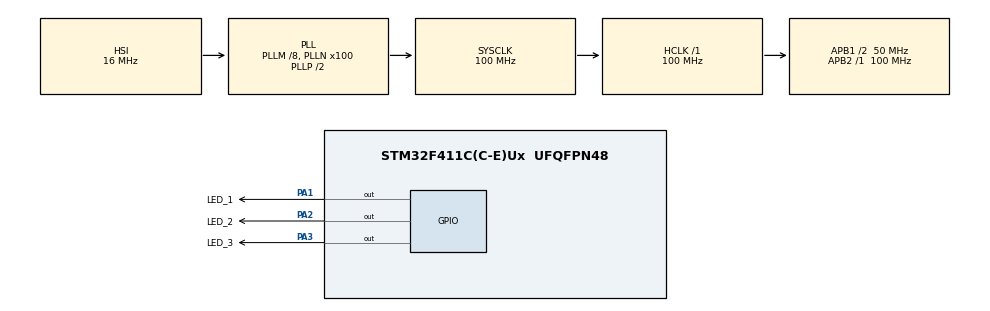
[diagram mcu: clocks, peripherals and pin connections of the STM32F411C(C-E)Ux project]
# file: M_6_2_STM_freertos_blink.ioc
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FREERTOS.Tasks01=defaultTask,24,128,StartDefaultTask,Default,NULL,Dynamic,NULL,NULL;myLedTask01,24,128,StartLedTask01,Default,NULL,Dynamic,NULL,NULL;myLedTask02,24,128,StartLedTask02,Default,NULL,Dynamic,NULL,NULL;myLedTask03,24,128,StartLedTask03,Default,NULL,Dynamic,NULL,NULL
FREERTOS.configUSE_NEWLIB_REENTRANT=1
Mcu.Family=STM32F4
Mcu.Name=STM32F411C(C-E)Ux
Mcu.Package=UFQFPN48
NVIC.PriorityGroup=NVIC_PRIORITYGROUP_4
NVIC.TIM2_IRQn=true\:15\:0\:false\:false\:true\:false\:false\:true\:true
NVIC.TimeBase=TIM2_IRQn
NVIC.TimeBaseIP=TIM2
PA1.GPIO_Label=LED_1
PA1.Signal=GPIO_Output
PA13.Mode=Serial_Wire
PA13.Signal=SYS_JTMS-SWDIO
PA14.Mode=Serial_Wire
PA14.Signal=SYS_JTCK-SWCLK
PA2.GPIO_Label=LED_2
PA2.Signal=GPIO_Output
PA3.GPIO_Label=LED_3
PA3.Signal=GPIO_Output
PC14-OSC32_IN.Mode=LSE-External-Oscillator
PC14-OSC32_IN.Signal=RCC_OSC32_IN
PC15-OSC32_OUT.Mode=LSE-External-Oscillator
PC15-OSC32_OUT.Signal=RCC_OSC32_OUT
PH0\ -\ OSC_IN.Mode=HSE-External-Oscillator
PH0\ -\ OSC_IN.Signal=RCC_OSC_IN
PH1\ -\ OSC_OUT.Mode=HSE-External-Oscillator
PH1\ -\ OSC_OUT.Signal=RCC_OSC_OUT
ProjectManager.HeapSize=0x200
ProjectManager.StackSize=0x400
ProjectManager.TargetToolchain=STM32CubeIDE
RCC.48MHZClocksFreq_Value=50000000
RCC.AHBFreq_Value=100000000
RCC.APB1CLKDivider=RCC_HCLK_DIV2
RCC.APB1Freq_Value=50000000
RCC.APB1TimFreq_Value=100000000
RCC.APB2Freq_Value=100000000
RCC.APB2TimFreq_Value=100000000
RCC.CortexFreq_Value=100000000
RCC.HCLKFreq_Value=100000000
RCC.HSE_VALUE=25000000
RCC.HSI_VALUE=16000000
RCC.PLLM=8
RCC.PLLN=100
RCC.SYSCLKFreq_VALUE=100000000
RCC.SYSCLKSource=RCC_SYSCLKSOURCE_PLLCLK
RCC.VCOOutputFreq_Value=200000000
VP_FREERTOS_VS_CMSIS_V2.Mode=CMSIS_V2
VP_SYS_VS_tim2.Mode=TIM2
board=custom

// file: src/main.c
/* USER CODE BEGIN Header */
/**
 ******************************************************************************
 * @file           : main.c
 * @brief          : Main program body
 ******************************************************************************
 * @attention
 *
 * Copyright (c) 2026 STMicroelectronics.
 * All rights reserved.
 *
 * This software is licensed under terms that can be found in the LICENSE file
 * in the root directory of this software component.
 * If no LICENSE file comes with this software, it is provided AS-IS.
 *
 ******************************************************************************
 */
/* USER CODE END Header */
#include "main.h"
#include "cmsis_os.h"

/* Definitions for defaultTask */
osThreadId_t defaultTaskHandle;
const osThreadAttr_t defaultTask_attributes = {
    .name = "defaultTask",
    .stack_size = 128 * 4,
    .priority = (osPriority_t)osPriorityNormal,
};
/* Definitions for myLedTask01 */
osThreadId_t myLedTask01Handle;
const osThreadAttr_t myLedTask01_attributes = {
    .name = "myLedTask01",
    .stack_size = 128 * 4,
    .priority = (osPriority_t)osPriorityNormal,
};
/* Definitions for myLedTask02 */
osThreadId_t myLedTask02Handle;
const osThreadAttr_t myLedTask02_attributes = {
    .name = "myLedTask02",
    .stack_size = 128 * 4,
    .priority = (osPriority_t)osPriorityNormal,
};
/* Definitions for myLedTask03 */
osThreadId_t myLedTask03Handle;
const osThreadAttr_t myLedTask03_attributes = {
    .name = "myLedTask03",
    .stack_size = 128 * 4,
    .priority = (osPriority_t)osPriorityNormal,
};

void SystemClock_Config(void);
static void MX_GPIO_Init(void);
void StartDefaultTask(void *argument);
void StartLedTask01(void *argument);
void StartLedTask02(void *argument);
void StartLedTask03(void *argument);

int main(void)
{

  /* MCU Configuration--------------------------------------------------------*/

  /* Reset of all peripherals, Initializes the Flash interface and the Systick. */
  HAL_Init();

  /* Configure the system clock */
  SystemClock_Config();

  /* Initialize all configured peripherals */
  MX_GPIO_Init();

  /* Init scheduler */
  osKernelInitialize();

  /* Create the thread(s) */
  /* creation of defaultTask */
  defaultTaskHandle = osThreadNew(StartDefaultTask, NULL, &defaultTask_attributes);

  /* creation of myLedTask01 */
  myLedTask01Handle = osThreadNew(StartLedTask01, NULL, &myLedTask01_attributes);

  /* creation of myLedTask02 */
  myLedTask02Handle = osThreadNew(StartLedTask02, NULL, &myLedTask02_attributes);

  /* creation of myLedTask03 */
  myLedTask03Handle = osThreadNew(StartLedTask03, NULL, &myLedTask03_attributes);

  /* Start scheduler */
  osKernelStart();

  /* We should never get here as control is now taken by the scheduler */

  /* Infinite loop */
  while (1)
  {

  }
}

void SystemClock_Config(void)
{
  RCC_OscInitTypeDef RCC_OscInitStruct = {0};
  RCC_ClkInitTypeDef RCC_ClkInitStruct = {0};

  /** Configure the main internal regulator output voltage
   */
  __HAL_RCC_PWR_CLK_ENABLE();
  __HAL_PWR_VOLTAGESCALING_CONFIG(PWR_REGULATOR_VOLTAGE_SCALE1);

  /** Initializes the RCC Oscillators according to the specified parameters
   * in the RCC_OscInitTypeDef structure.
   */
  RCC_OscInitStruct.OscillatorType = RCC_OSCILLATORTYPE_HSI;
  RCC_OscInitStruct.HSIState = RCC_HSI_ON;
  RCC_OscInitStruct.HSICalibrationValue = RCC_HSICALIBRATION_DEFAULT;
  RCC_OscInitStruct.PLL.PLLState = RCC_PLL_ON;
  RCC_OscInitStruct.PLL.PLLSource = RCC_PLLSOURCE_HSI;
  RCC_OscInitStruct.PLL.PLLM = 8;
  RCC_OscInitStruct.PLL.PLLN = 100;
  RCC_OscInitStruct.PLL.PLLP = RCC_PLLP_DIV2;
  RCC_OscInitStruct.PLL.PLLQ = 4;
  if (HAL_RCC_OscConfig(&RCC_OscInitStruct) != HAL_OK)
  {
    Error_Handler();
  }

  /** Initializes the CPU, AHB and APB buses clocks
   */
  RCC_ClkInitStruct.ClockType = RCC_CLOCKTYPE_HCLK | RCC_CLOCKTYPE_SYSCLK | RCC_CLOCKTYPE_PCLK1 | RCC_CLOCKTYPE_PCLK2;
  RCC_ClkInitStruct.SYSCLKSource = RCC_SYSCLKSOURCE_PLLCLK;
  RCC_ClkInitStruct.AHBCLKDivider = RCC_SYSCLK_DIV1;
  RCC_ClkInitStruct.APB1CLKDivider = RCC_HCLK_DIV2;
  RCC_ClkInitStruct.APB2CLKDivider = RCC_HCLK_DIV1;

  if (HAL_RCC_ClockConfig(&RCC_ClkInitStruct, FLASH_LATENCY_3) != HAL_OK)
  {
    Error_Handler();
  }
}

static void MX_GPIO_Init(void)
{
  GPIO_InitTypeDef GPIO_InitStruct = {0};

  /* GPIO Ports Clock Enable */
  __HAL_RCC_GPIOC_CLK_ENABLE();
  __HAL_RCC_GPIOH_CLK_ENABLE();
  __HAL_RCC_GPIOA_CLK_ENABLE();

  /*Configure GPIO pin Output Level */
  HAL_GPIO_WritePin(GPIOA, LED_1_Pin | LED_2_Pin | LED_3_Pin, GPIO_PIN_RESET);

  /*Configure GPIO pins : LED_1_Pin LED_2_Pin LED_3_Pin */
  GPIO_InitStruct.Pin = LED_1_Pin | LED_2_Pin | LED_3_Pin;
  GPIO_InitStruct.Mode = GPIO_MODE_OUTPUT_PP;
  GPIO_InitStruct.Pull = GPIO_NOPULL;
  GPIO_InitStruct.Speed = GPIO_SPEED_FREQ_LOW;
  HAL_GPIO_Init(GPIOA, &GPIO_InitStruct);

}

void StartDefaultTask(void *argument)
{
  for (;;)
  {
    osDelay(1);
  }
}

void StartLedTask01(void *argument)
{
  /* USER CODE BEGIN StartLedTask01 */
  /* Infinite loop */
  for (;;)
  {
    HAL_GPIO_WritePin(GPIOA, LED_1_Pin, GPIO_PIN_SET);
    osDelay(500);
    HAL_GPIO_WritePin(GPIOA, LED_1_Pin, GPIO_PIN_RESET);
    osDelay(500);
  }
  /* USER CODE END StartLedTask01 */
}

void StartLedTask02(void *argument)
{
  /* USER CODE BEGIN StartLedTask02 */
  /* Infinite loop */
  for (;;)
  {
    HAL_GPIO_WritePin(GPIOA, LED_2_Pin, GPIO_PIN_SET);
    osDelay(300);
    HAL_GPIO_WritePin(GPIOA, LED_2_Pin, GPIO_PIN_RESET);
    osDelay(300);
  }
  /* USER CODE END StartLedTask02 */
}

void StartLedTask03(void *argument)
{
  /* USER CODE BEGIN StartLedTask03 */
  /* Infinite loop */
  for (;;)
  {
    HAL_GPIO_WritePin(GPIOA, LED_3_Pin, GPIO_PIN_SET);
    osDelay(100);
    HAL_GPIO_WritePin(GPIOA, LED_3_Pin, GPIO_PIN_RESET);
    osDelay(100);
  }
  /* USER CODE END StartLedTask03 */
}

void HAL_TIM_PeriodElapsedCallback(TIM_HandleTypeDef *htim)
{
  if (htim->Instance == TIM2)
  {
    HAL_IncTick();
  }
}

void Error_Handler(void)
{
  __disable_irq();
  while (1)
  {
  }
}
